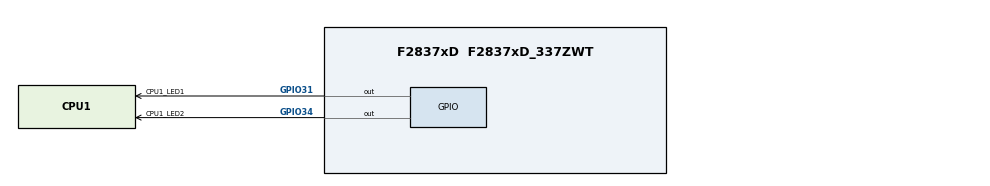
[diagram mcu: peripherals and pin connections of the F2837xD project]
/**
 * @cliArgs --device "F2837xD" --package "F2837xD_337ZWT" --part "F2837xD_337ZWT" --context "CPU1" --product "C2000WARE@4.03.00.00"
 * @versions {"tool":"1.15.999+71"}
 */

/**
 * Import the modules used in this configuration.
 */
const dma    = scripting.addModule("/driverlib/dma.js", {}, false);
const dma1   = dma.addInstance();
const epwm   = scripting.addModule("/driverlib/epwm.js", {}, false);
const epwm1  = epwm.addInstance();
const gpio   = scripting.addModule("/driverlib/gpio.js", {}, false);
const gpio1  = gpio.addInstance();
const gpio2  = gpio.addInstance();
const ipc    = scripting.addModule("/driverlib/ipc.js");
const memcfg = scripting.addModule("/driverlib/memcfg.js");
const sysctl = scripting.addModule("/driverlib/sysctl.js");

/**
 * Write custom configuration values to the imported modules.
 */
dma1.$name                = "myDMA5";
dma1.dmaBase              = "DMA_CH5_BASE";
dma1.enableTriggers       = true;
dma1.triggerSource        = "DMA_TRIGGER_SPIATX";
dma1.useInterrupts        = true;
dma1.enableInterrupts     = true;
dma1.interruptMode        = "DMA_INT_AT_END";
dma1.oneShotConfig        = "DMA_CFG_ONESHOT_ENABLE";
dma1.continuousModeConfig = "DMA_CFG_CONTINUOUS_ENABLE";
dma1.startChannel         = true;
dma1.srcBurstStep         = 1;
dma1.srcTransferStep      = 1;
dma1.destBurstStep        = 1;
dma1.destTransferStep     = 1;

epwm1.$name                                                      = "myEPWM0";
epwm1.epwmTimebase_clockDiv                                      = "EPWM_CLOCK_DIVIDER_4";
epwm1.epwmTimebase_hsClockDiv                                    = "EPWM_HSCLOCK_DIVIDER_4";
epwm1.epwmTimebase_period                                        = 6000;
epwm1.epwmTimebase_counterMode                                   = "EPWM_COUNTER_MODE_UP_DOWN";
epwm1.epwmTimebase_syncOutPulseMode                              = "EPWM_SYNC_OUT_PULSE_DISABLED";
epwm1.epwmCounterCompare_cmpA                                    = 3000;
epwm1.epwmActionQualifier_EPWM_AQ_OUTPUT_A_ON_TIMEBASE_UP_CMPA   = "EPWM_AQ_OUTPUT_HIGH";
epwm1.epwmActionQualifier_EPWM_AQ_OUTPUT_A_ON_TIMEBASE_DOWN_CMPA = "EPWM_AQ_OUTPUT_LOW";
epwm1.epwmActionQualifier_EPWM_AQ_OUTPUT_B_ON_TIMEBASE_UP_CMPA   = "EPWM_AQ_OUTPUT_LOW";
epwm1.epwmActionQualifier_EPWM_AQ_OUTPUT_B_ON_TIMEBASE_DOWN_CMPA = "EPWM_AQ_OUTPUT_HIGH";
epwm1.epwm.$assign                                               = "EPWM1";

gpio1.direction       = "GPIO_DIR_MODE_OUT";
gpio1.$name           = "CPU1_LED1";
gpio1.gpioPin.$assign = "GPIO31";

gpio2.$name           = "CPU1_LED2";
gpio2.direction       = "GPIO_DIR_MODE_OUT";
gpio2.gpioPin.$assign = "GPIO34";

memcfg.config_MEMCFG_SECT_GS2 = "MEMCFG_GSRAMCONTROLLER_CPU2";

sysctl.enable_SYSCTL_PERIPH_CLK_TBCLKSYNC = true;
sysctl.cpuSel_SPIC                        = "SYSCTL_CPUSEL_CPU2";
sysctl.secMasterFrame1                    = "SYSCTL_SEC_CONTROLLER_DMA";
sysctl.cpuSel_SPIA                        = "SYSCTL_CPUSEL_CPU2";
sysctl.secMasterFrame2                    = "SYSCTL_SEC_CONTROLLER_DMA";

/**
 * Pinmux solution for unlocked pins/peripherals. This ensures that minor changes to the automatic solver in a future
 * version of the tool will not impact the pinmux you originally saw.  These lines can be completely deleted in order to
 * re-solve from scratch.
 */
epwm1.epwm.epwm_aPin.$suggestSolution = "GPIO0";
epwm1.epwm.epwm_bPin.$suggestSolution = "GPIO1";
